# CMS32L032 register map
Vendor: CMS; Series: CMS32L032; File version: 1.2
CPU: CM0+ r0p1, little endian, no MPU, no FPU, VTOR, 2 interrupt priority bits
Registers are 8-bit, read-write, reset 0x0 unless marked. A register's access mark holds for its fields unless they carry their own. Offsets are from the block's base; [hi:lo] are bit positions; lines under a group give offsets from that group; {n}, {i} and the like mark numbered series.

## SPI — Serial Interface SPI
Base 0x40042400
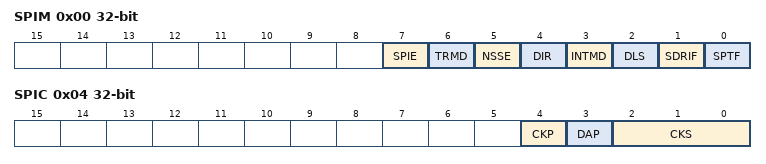
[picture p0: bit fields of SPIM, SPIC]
0x00 SPIM 32-bit — SPI mode control register
  [7] SPIE — SPI operation enable
  [6] TRMD — Transfer and Receive mode
  [5] NSSE — NSS pin enable
  [4] DIR — MSB of LSB mode select
  [3] INTMD — interrupt source select
  [2] DLS — data length control
  [1] SDRIF — Receive buffer non-empty flag
  [0] SPTF — SPI transmission status flag
0x04 SPIC 32-bit — SPI control register
  [4] CKP — Selection of clock phase for SPI
  [3] DAP — Selection of data phase for SPI
  [2:0] CKS — Operation clock control
0x08 SDRO 32-bit (reset mask 0xFFFF) — Data buffer of transmission
0x0C SDRI 32-bit (reset mask 0xFFFF) — Data buffer of reception

## IICA — Serial Interface I2C with multimaster and wakeup supported
Base 0x40041A30
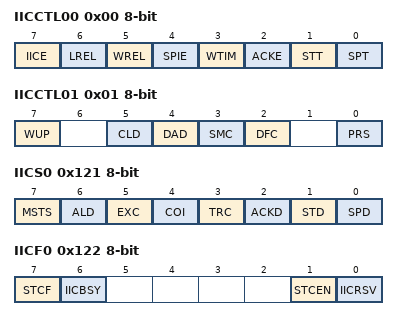
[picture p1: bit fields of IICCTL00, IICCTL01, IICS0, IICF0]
0x00 IICCTL00 — IICA control register 0
  [7] IICE — I2C operation enable
  [6] LREL — Exit from communications
  [5] WREL — Wait cancellation
  [4] SPIE — Enable generation of interrupt request when stop condition is detected
  [3] WTIM — Control of wait and interrupt request generation
  [2] ACKE — Acknowledgment control
  [1] STT — Start condition trigger
  [0] SPT — Stop condition trigger
0x01 IICCTL01 — IICA control register 0
  [7] WUP — Control of address match wakeup
  [5] CLD ro — Detection of SCLAn pin level (valid only when IICEn = 1)
  [4] DAD ro — Detection of SDAAn pin level (valid only when IICEn = 1)
  [3] SMC — Operation mode switching
  [2] DFC — Digital filter operation control
  [0] PRS — Operation clock (fMCK) contro
0x02 IICWL0 reset 0xFF — IICA low-level width setting register 0
0x03 IICWH0 reset 0xFF — IICA high-level width setting register 0
0x04 SVA0 (reset mask 0xFE) — Slave address register 0
0x120 IICA0 — IICA shift register 0
0x121 IICS0 ro — IICA status register 0
  [7] MSTS — Master status check flag
  [6] ALD — Detection of arbitration loss
  [5] EXC — Detection of extension code reception
  [4] COI — Detection of matching addresses
  [3] TRC — Detection of transmit/receive status
  [2] ACKD — Detection of acknowledge (ACK)
  [1] STD — Detection of start condition
  [0] SPD — Detection of stop condition
0x122 IICF0 — IICA flag register 0
  [7] STCF ro — STT clear flag
  [6] IICBSY ro — I2C bus status flag
  [1] STCEN — Initial start enable trigger
  [0] IICRSV — Communication reservation function disable bit

## IRDA — IrDA communication module based on Infrared Data Association stardard 1.0
Base 0x400440A0
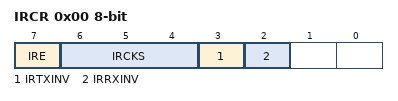
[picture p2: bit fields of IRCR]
0x00 IRCR — IrDA control register
  [7] IRE — IrRxD enable
  [6:4] IRCKS — IrRxD clock selection
  [3] IRTXINV — IrRxD data polarity switching
  [2] IRRXINV — IrRxD data polarity switching

## ELC — Event Link Controller
Base 0x40043400
{0x0+i} ELSELR{i:02} (reset mask 0xF) (i=0..14) — Event output destination select register {i:02}

## INT — Interrupt Controller
Base 0x40006000
{0x0+4i} IF[{i}] (i=0..31) group — Interrupt flag register
  0x00 IFL (reset mask 0x1) — Interrupt flag register
{0x100+4i} MK[{i}] (i=0..31) group — Interrupt mask register
  0x00 MKL reset 0xFFFFFFFF (reset mask 0x1) — Interrupt mask register

## INTM — Pin input edge detection
Base 0x40045B38
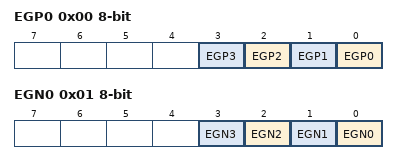
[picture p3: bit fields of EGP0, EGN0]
0x00 EGP0 — External interrupt rising edge enable register
  [n] EGP{n} (n=0..3)
0x01 EGN0 — External interrupt falling edge enable register
  [n] EGN{n} (n=0..3)

## KEY — Key interrupt
Base 0x40044B30
0x07 KRM (reset mask 0x3F) — Key return mode register

## MISC — Miscellaneous function
Base 0x40040470
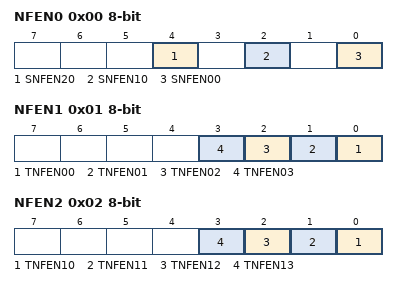
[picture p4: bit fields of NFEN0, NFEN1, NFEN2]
0x00 NFEN0 — Noise filter enable register 0
  [4] SNFEN20 — Enable noise filter of RxD2
  [2] SNFEN10 — Enable noise filter of RxD1
  [0] SNFEN00 — Enable noise filter of RxD0
0x01 NFEN1 — Noise filter enable register 1
  [n] TNFEN{n:02} (n=0..3) — Enable noise filter of TI{n:02}
0x02 NFEN2 — Noise filter enable register 2
  [n-10] TNFEN{n} (n=10..13) — Enable noise filter of TI{n}
0x03 ISC — Input switch control register
  [7] SSIE00 — The slave select input (SS00) of SPI00 is valid
    0=INVALID (The slave select input (SS00) pin is invalid); 1=VALID (The slave select input (SS00) pin is valid)
0x04 TIOS0 (reset mask 0x83) — Timer I/O select register 0
0x05 TIOS1 (reset mask 0x1) — Timer I/O select register 1
0x0C RTCCL (reset mask 0xE3) — Real-time clock select register

## FMC — Flash Memory Controller
Base 0x40020000
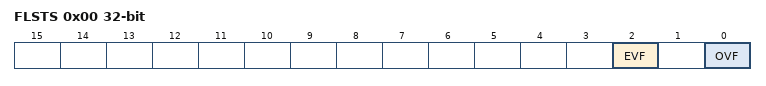
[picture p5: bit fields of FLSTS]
0x00 FLSTS 32-bit — Flash status register
  [2] EVF — Flash hardware verification error flag
  [0] OVF — Flash erase or write operaiton finish
0x04 FLOPMD1 32-bit (reset mask 0xFF) — Flash operation mode register 1
0x08 FLOPMD2 32-bit (reset mask 0xFF) — Flash operation mode register 2
0x0C FLERMD 32-bit (reset mask 0x18) — Flash erase mode register
0x10 FLCERCNT 32-bit (reset mask 0x800001FF) — Flash chip erase control register
0x14 FLSERCNT 32-bit (reset mask 0x800001FF) — Flash sector erase control register
0x18 FLNVSCNT 32-bit (reset mask 0x800001FF) — Flash address setup time (Tnvs) control register
0x1C FLPROCNT 32-bit (reset mask 0x81FF81FF) — Flash program control register
0x20 FLPROT 32-bit (reset mask 0xFF) — Flash protect control register
0x38 FLPRVCNT 32-bit (reset mask 0x800001FF) — Flash program recovery time (Trcv) control register
0x3C FLERVCNT 32-bit (reset mask 0x803FF81FF) — Flash erase recovery time (Trcv) control register

## SAF — Flash memory CRC operation function (High-Speed CRC)
Base 0x40020100
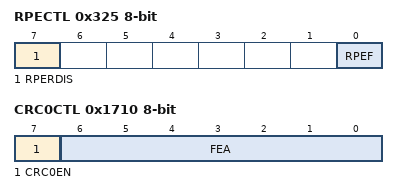
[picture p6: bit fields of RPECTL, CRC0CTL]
0x325 RPECTL — RAM parity error control register
  [7] RPERDIS — Disable RAM parity error reset
    0=Enable parity error reset; 1=Disable parity error reset
  [0] RPEF — Parity error status flag
    0=NoError (No parity error has occurred); 1=Error (Parity error has occurred)
0x1710 CRC0CTL — Flash memory CRC control register
  [7] CRC0EN — Control of high-speed CRC operation
  [6:0] FEA — High-speed CRC operation range
0x1712 PGCRCL 16-bit — Flash memory CRC operation result register
0x20378 SFRGD 16-bit (reset mask 0xF) — SFR guard control register
0x231FA CRCD 16-bit (reset mask 0xFF) — CRC data register
0x232AC CRCIN — CRC input register

## CRC — General Purpose CRC
Base 0x400432F0
0x0A CRCD 16-bit (reset mask 0xFF) — CRC data register
0xBC CRCIN — CRC input register

## DBG — DBG Controller
Base 0x4001B000
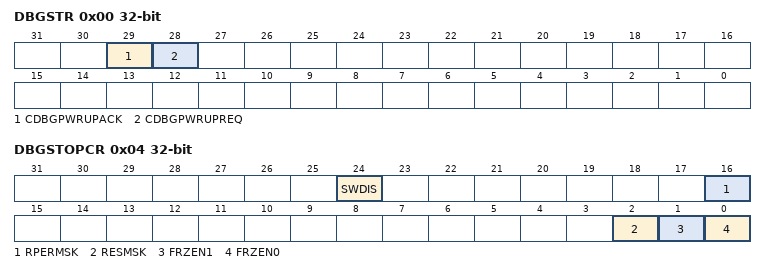
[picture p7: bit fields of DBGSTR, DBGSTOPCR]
0x00 DBGSTR 32-bit ro — Debug status register
  [29] CDBGPWRUPACK — DBG Power Up Acknowledgement
  [28] CDBGPWRUPREQ — DBG Power Up Request
0x04 DBGSTOPCR 32-bit — Debug Stop Control register
  [24] SWDIS — SWD Disable
  [16] RPERMSK — Mask RAM parity error in debug mode
  [2] RESMSK — Mask internal reset in debug mode
  [1] FRZEN1 — Stop Communation family macros when cpu halted
  [0] FRZEN0 — Stop Timer family macros when cpu halted

## BGR — Temperature Sensor calibration data
Base 0x00500660
0x00 VBG85 16-bit ro — The A/D conversion value of VBGR at 85 degrees and 3.0V reference voltage
0x04 VBG25 16-bit ro — The A/D conversion value of VBGR at 25 degrees and 3.0V reference voltage

## TSN — Temperature Sensor calibration data
Base 0x00500668
0x00 TSN85 16-bit ro — The A/D conversion value of Temperature Sensor at 85 degrees and 3.0V reference voltage
0x04 TSN25 16-bit ro — The A/D conversion value of Temperature Sensor at 25 degrees and 3.0V reference voltage

## UID — 128-bit Unique ID
Base 0x00500894
{0x0+4i} UID{i} (i=0..3) 32-bit ro — UID word {i}
